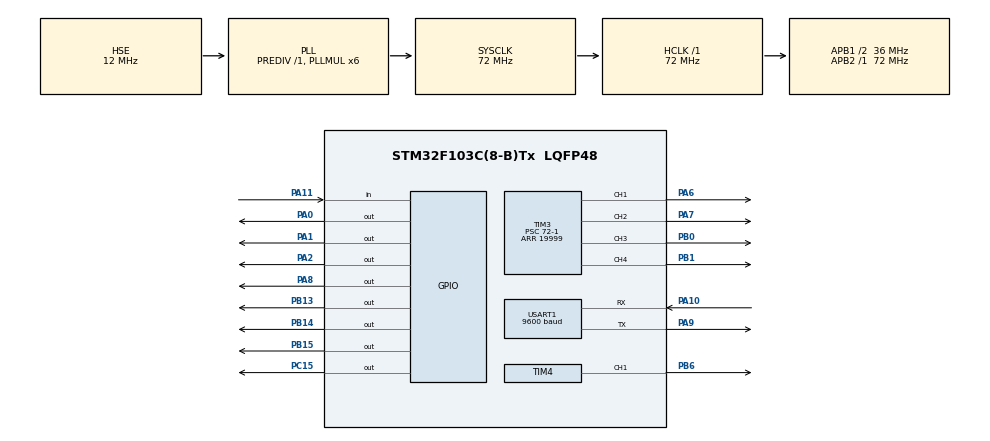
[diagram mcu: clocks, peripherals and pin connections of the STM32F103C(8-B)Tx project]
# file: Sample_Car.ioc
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Dma.Request0=USART1_RX
Dma.Request1=USART1_TX
Dma.USART1_RX.0.Direction=DMA_PERIPH_TO_MEMORY
Dma.USART1_RX.0.Instance=DMA1_Channel5
Dma.USART1_RX.0.MemDataAlignment=DMA_MDATAALIGN_BYTE
Dma.USART1_RX.0.MemInc=DMA_MINC_ENABLE
Dma.USART1_RX.0.Mode=DMA_CIRCULAR
Dma.USART1_RX.0.PeriphDataAlignment=DMA_PDATAALIGN_BYTE
Dma.USART1_RX.0.PeriphInc=DMA_PINC_DISABLE
Dma.USART1_RX.0.Priority=DMA_PRIORITY_LOW
Dma.USART1_TX.1.Direction=DMA_MEMORY_TO_PERIPH
Dma.USART1_TX.1.Instance=DMA1_Channel4
Dma.USART1_TX.1.MemDataAlignment=DMA_MDATAALIGN_BYTE
Dma.USART1_TX.1.MemInc=DMA_MINC_ENABLE
Dma.USART1_TX.1.Mode=DMA_NORMAL
Dma.USART1_TX.1.PeriphDataAlignment=DMA_PDATAALIGN_BYTE
Dma.USART1_TX.1.PeriphInc=DMA_PINC_DISABLE
Dma.USART1_TX.1.Priority=DMA_PRIORITY_LOW
FREERTOS.Tasks01=defaultTask,-3,128,StartDefaultTask,As weak,NULL,Dynamic,NULL,NULL;MoveTask,-1,256,StartMoveTask,As weak,NULL,Dynamic,NULL,NULL;BlueToothTask,0,256,StartBlueToothTask,As weak,NULL,Dynamic,NULL,NULL;ArmTask,-2,256,StartArmTask,As weak,NULL,Dynamic,NULL,NULL
FREERTOS.configTOTAL_HEAP_SIZE=8192
Mcu.Family=STM32F1
Mcu.Name=STM32F103C(8-B)Tx
Mcu.Package=LQFP48
NVIC.DMA1_Channel4_IRQn=true\:5\:0\:false\:false\:true\:true\:false\:true\:true
NVIC.DMA1_Channel5_IRQn=true\:5\:0\:false\:false\:true\:true\:false\:true\:true
NVIC.PriorityGroup=NVIC_PRIORITYGROUP_4
NVIC.TIM2_IRQn=true\:15\:0\:false\:false\:true\:false\:false\:true\:true
NVIC.TimeBase=TIM2_IRQn
NVIC.TimeBaseIP=TIM2
NVIC.USART1_IRQn=true\:5\:0\:false\:false\:true\:true\:true\:true\:true
PA0-WKUP.Signal=GPIO_Output
PA1.Signal=GPIO_Output
PA10.Mode=Asynchronous
PA10.Signal=USART1_RX
PA11.GPIO_PuPd=GPIO_PULLDOWN
PA11.Signal=GPIO_Input
PA13.Mode=Serial_Wire
PA13.Signal=SYS_JTMS-SWDIO
PA14.Mode=Serial_Wire
PA14.Signal=SYS_JTCK-SWCLK
PA2.Signal=GPIO_Output
PA6.Signal=S_TIM3_CH1
PA7.Signal=S_TIM3_CH2
PA8.Signal=GPIO_Output
PA9.Mode=Asynchronous
PA9.Signal=USART1_TX
PB0.Signal=S_TIM3_CH3
PB1.Signal=S_TIM3_CH4
PB13.Signal=GPIO_Output
PB14.Signal=GPIO_Output
PB15.Signal=GPIO_Output
PB6.Signal=S_TIM4_CH1
PC15-OSC32_OUT.Signal=GPIO_Output
PD0-OSC_IN.Mode=HSE-External-Oscillator
PD0-OSC_IN.Signal=RCC_OSC_IN
PD1-OSC_OUT.Mode=HSE-External-Oscillator
PD1-OSC_OUT.Signal=RCC_OSC_OUT
ProjectManager.HeapSize=0x200
ProjectManager.StackSize=0x400
ProjectManager.TargetToolchain=CMake
RCC.AHBFreq_Value=72000000
RCC.APB1CLKDivider=RCC_HCLK_DIV2
RCC.APB1Freq_Value=36000000
RCC.APB1TimFreq_Value=72000000
RCC.APB2Freq_Value=72000000
RCC.APB2TimFreq_Value=72000000
RCC.HCLKFreq_Value=72000000
RCC.HSE_VALUE=12000000
RCC.PLLMUL=RCC_PLL_MUL6
RCC.PLLSourceVirtual=RCC_PLLSOURCE_HSE
RCC.SYSCLKFreq_VALUE=72000000
RCC.SYSCLKSource=RCC_SYSCLKSOURCE_PLLCLK
RCC.USBFreq_Value=72000000
SH.S_TIM3_CH1.0=TIM3_CH1,PWM Generation1 CH1
SH.S_TIM3_CH2.0=TIM3_CH2,PWM Generation2 CH2
SH.S_TIM3_CH3.0=TIM3_CH3,PWM Generation3 CH3
SH.S_TIM3_CH4.0=TIM3_CH4,PWM Generation4 CH4
SH.S_TIM4_CH1.0=TIM4_CH1,PWM Generation1 CH1
TIM3.Channel-PWM\ Generation1\ CH1=TIM_CHANNEL_1
TIM3.Channel-PWM\ Generation2\ CH2=TIM_CHANNEL_2
TIM3.Channel-PWM\ Generation3\ CH3=TIM_CHANNEL_3
TIM3.Channel-PWM\ Generation4\ CH4=TIM_CHANNEL_4
TIM3.Period=19999
TIM3.Prescaler=72-1
TIM4.Channel-PWM\ Generation1\ CH1=TIM_CHANNEL_1
TIM4.Period=19999
TIM4.Prescaler=72-1
USART1.BaudRate=9600
USART1.VirtualMode=VM_ASYNC
VP_FREERTOS_VS_CMSIS_V1.Mode=CMSIS_V1
VP_SYS_VS_tim2.Mode=TIM2
board=custom

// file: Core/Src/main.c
/* USER CODE BEGIN Header */
/**
  ******************************************************************************
  * @file           : main.c
  * @brief          : Main program body
  ******************************************************************************
  * @attention
  *
  * Copyright (c) 2026 STMicroelectronics.
  * All rights reserved.
  *
  * This software is licensed under terms that can be found in the LICENSE file
  * in the root directory of this software component.
  * If no LICENSE file comes with this software, it is provided AS-IS.
  *
  ******************************************************************************
  */
/* USER CODE END Header */
#include "main.h"
#include "cmsis_os.h"
#include "dma.h"
#include "tim.h"
#include "usart.h"
#include "gpio.h"

/* USER CODE BEGIN Includes */
#include "CYT_IRQN.h"
/* USER CODE END Includes */

void SystemClock_Config(void);
void MX_FREERTOS_Init(void);

int main(void)
{

  /* MCU Configuration--------------------------------------------------------*/

  /* Reset of all peripherals, Initializes the Flash interface and the Systick. */
  HAL_Init();

  /* Configure the system clock */
  SystemClock_Config();

  /* Initialize all configured peripherals */
  MX_GPIO_Init();
  MX_DMA_Init();
  MX_TIM3_Init();
  MX_TIM4_Init();
  MX_USART1_UART_Init();
  /* USER CODE BEGIN 2 */
  /* 队列/信号量/电机/舵机全部在调度器启动前初始化完成 */
  EverythingInit();
  /* USER CODE END 2 */

  /* Call init function for freertos objects (in cmsis_os2.c) */
  MX_FREERTOS_Init();

  /* Start scheduler */
  osKernelStart();

  /* We should never get here as control is now taken by the scheduler */

  /* Infinite loop */
  while (1)
  {

  }
}

void SystemClock_Config(void)
{
  RCC_OscInitTypeDef RCC_OscInitStruct = {0};
  RCC_ClkInitTypeDef RCC_ClkInitStruct = {0};

  /** Initializes the RCC Oscillators according to the specified parameters
  * in the RCC_OscInitTypeDef structure.
  */
  RCC_OscInitStruct.OscillatorType = RCC_OSCILLATORTYPE_HSE;
  RCC_OscInitStruct.HSEState = RCC_HSE_ON;
  RCC_OscInitStruct.HSEPredivValue = RCC_HSE_PREDIV_DIV1;
  RCC_OscInitStruct.HSIState = RCC_HSI_ON;
  RCC_OscInitStruct.PLL.PLLState = RCC_PLL_ON;
  RCC_OscInitStruct.PLL.PLLSource = RCC_PLLSOURCE_HSE;
  RCC_OscInitStruct.PLL.PLLMUL = RCC_PLL_MUL6;
  if (HAL_RCC_OscConfig(&RCC_OscInitStruct) != HAL_OK)
  {
    Error_Handler();
  }

  /** Initializes the CPU, AHB and APB buses clocks
  */
  RCC_ClkInitStruct.ClockType = RCC_CLOCKTYPE_HCLK|RCC_CLOCKTYPE_SYSCLK
                              |RCC_CLOCKTYPE_PCLK1|RCC_CLOCKTYPE_PCLK2;
  RCC_ClkInitStruct.SYSCLKSource = RCC_SYSCLKSOURCE_PLLCLK;
  RCC_ClkInitStruct.AHBCLKDivider = RCC_SYSCLK_DIV1;
  RCC_ClkInitStruct.APB1CLKDivider = RCC_HCLK_DIV2;
  RCC_ClkInitStruct.APB2CLKDivider = RCC_HCLK_DIV1;

  if (HAL_RCC_ClockConfig(&RCC_ClkInitStruct, FLASH_LATENCY_2) != HAL_OK)
  {
    Error_Handler();
  }
}

void HAL_TIM_PeriodElapsedCallback(TIM_HandleTypeDef *htim)
{
  if (htim->Instance == TIM2)
  {
    HAL_IncTick();
  }
}

void Error_Handler(void)
{
  /* USER CODE BEGIN Error_Handler_Debug */
  /* 时钟/HSE 初始化失败会卡在这里：让 PB12（板载 LED）【快闪】。
   * 判读：
   *   PB12 快闪个不停  -> 卡在 Error_Handler，就是时钟没起来
   *   PB12 慢闪（1 秒）-> 程序正常在跑（CYT_IRQN.c 的心跳）
   *   PB12 完全不闪    -> 程序根本没运行（供电/烧录/复位问题）
   */
  {
    GPIO_InitTypeDef gpio = {0};
    volatile uint32_t i;

    __HAL_RCC_GPIOB_CLK_ENABLE();
    gpio.Pin   = GPIO_PIN_12;
    gpio.Mode  = GPIO_MODE_OUTPUT_PP;
    gpio.Pull  = GPIO_NOPULL;
    gpio.Speed = GPIO_SPEED_FREQ_LOW;
    HAL_GPIO_Init(GPIOB, &gpio);

    __disable_irq();
    for (;;)
    {
      HAL_GPIO_TogglePin(GPIOB, GPIO_PIN_12);
      for (i = 0; i < 100000u; i++)
      {
        /* 粗延时，做出"快闪"效果 */
      }
    }
  }
  /* USER CODE END Error_Handler_Debug */
}

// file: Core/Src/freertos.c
/* USER CODE BEGIN Header */
/**
  ******************************************************************************
  * File Name          : freertos.c
  * Description        : Code for freertos applications
  ******************************************************************************
  * @attention
  *
  * Copyright (c) 2026 STMicroelectronics.
  * All rights reserved.
  *
  * This software is licensed under terms that can be found in the LICENSE file
  * in the root directory of this software component.
  * If no LICENSE file comes with this software, it is provided AS-IS.
  *
  ******************************************************************************
  */
/* USER CODE END Header */

#include "FreeRTOS.h"
#include "task.h"
#include "main.h"
#include "cmsis_os.h"

osThreadId defaultTaskHandle;
osThreadId MoveTaskHandle;
osThreadId BlueToothTaskHandle;
osThreadId ArmTaskHandle;

void StartDefaultTask(void const * argument);
void StartMoveTask(void const * argument);
void StartBlueToothTask(void const * argument);
void StartArmTask(void const * argument);

void MX_FREERTOS_Init(void); /* (MISRA C 2004 rule 8.1) */

/* GetIdleTaskMemory prototype (linked to static allocation support) */
void vApplicationGetIdleTaskMemory( StaticTask_t **ppxIdleTaskTCBBuffer, StackType_t **ppxIdleTaskStackBuffer, uint32_t *pulIdleTaskStackSize );

/* USER CODE BEGIN GET_IDLE_TASK_MEMORY */
static StaticTask_t xIdleTaskTCBBuffer;
static StackType_t xIdleStack[configMINIMAL_STACK_SIZE];

void vApplicationGetIdleTaskMemory( StaticTask_t **ppxIdleTaskTCBBuffer, StackType_t **ppxIdleTaskStackBuffer, uint32_t *pulIdleTaskStackSize )
{
  *ppxIdleTaskTCBBuffer = &xIdleTaskTCBBuffer;
  *ppxIdleTaskStackBuffer = &xIdleStack[0];
  *pulIdleTaskStackSize = configMINIMAL_STACK_SIZE;
  /* place for user code */
}
/* USER CODE END GET_IDLE_TASK_MEMORY */

void MX_FREERTOS_Init(void) {

  /* Create the thread(s) */
  /* definition and creation of defaultTask */
  osThreadDef(defaultTask, StartDefaultTask, osPriorityIdle, 0, 128);
  defaultTaskHandle = osThreadCreate(osThread(defaultTask), NULL);

  /* definition and creation of MoveTask */
  osThreadDef(MoveTask, StartMoveTask, osPriorityBelowNormal, 0, 256);
  MoveTaskHandle = osThreadCreate(osThread(MoveTask), NULL);

  /* definition and creation of BlueToothTask */
  osThreadDef(BlueToothTask, StartBlueToothTask, osPriorityNormal, 0, 256);
  BlueToothTaskHandle = osThreadCreate(osThread(BlueToothTask), NULL);

  /* definition and creation of ArmTask */
  osThreadDef(ArmTask, StartArmTask, osPriorityLow, 0, 256);
  ArmTaskHandle = osThreadCreate(osThread(ArmTask), NULL);

}

__weak void StartDefaultTask(void const * argument)
{
  for(;;)
  {
    osDelay(1);
  }
}

__weak void StartMoveTask(void const * argument)
{
  for(;;)
  {
    osDelay(1);
  }
}

__weak void StartBlueToothTask(void const * argument)
{
  for(;;)
  {
    osDelay(1);
  }
}

__weak void StartArmTask(void const * argument)
{
  for(;;)
  {
    osDelay(1);
  }
}
